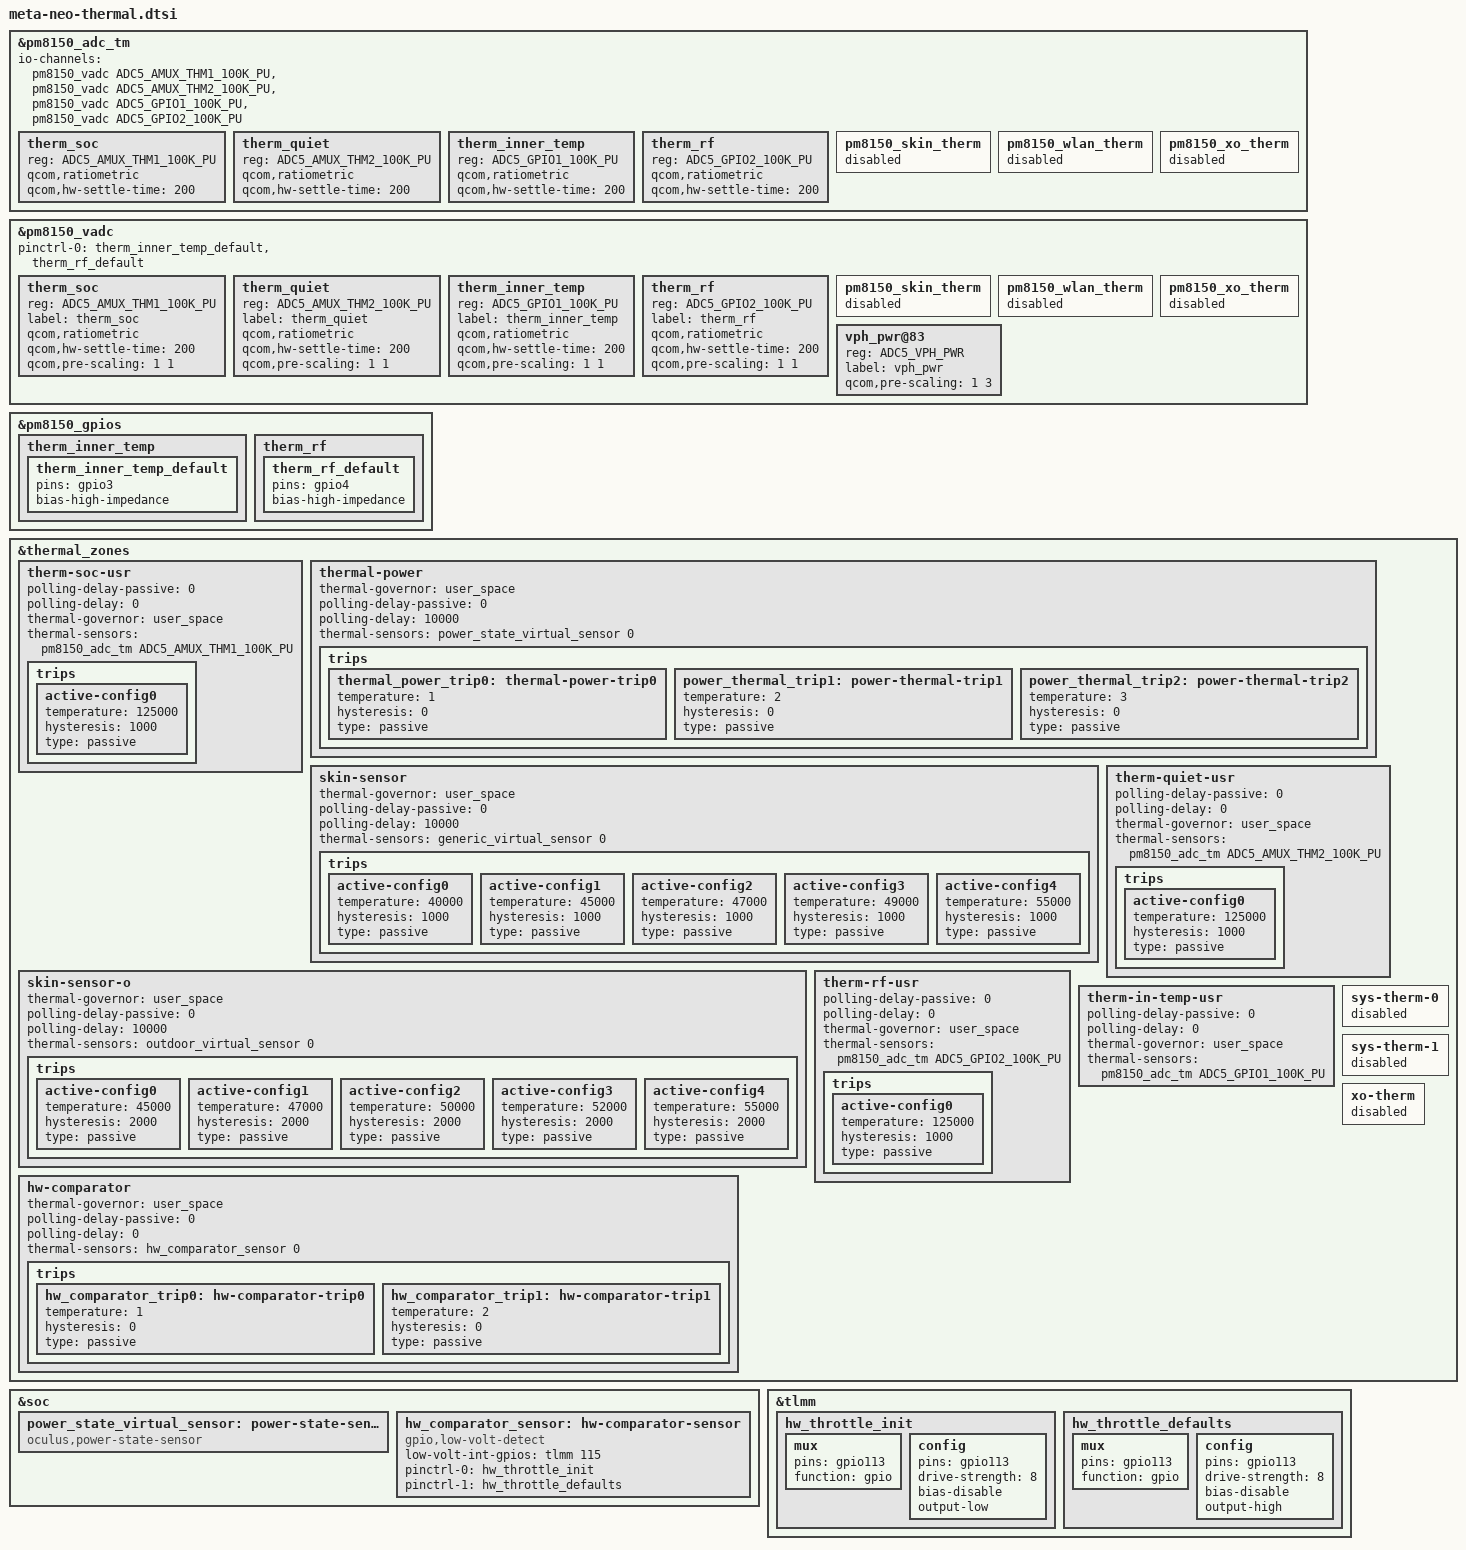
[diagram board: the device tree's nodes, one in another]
&pm8150_adc_tm {
	io-channels = <&pm8150_vadc ADC5_AMUX_THM1_100K_PU>,
				<&pm8150_vadc ADC5_AMUX_THM2_100K_PU>,
				<&pm8150_vadc ADC5_GPIO1_100K_PU>,
				<&pm8150_vadc ADC5_GPIO2_100K_PU>;

	therm_soc {
		reg = <ADC5_AMUX_THM1_100K_PU>;
		qcom,ratiometric;
		qcom,hw-settle-time = <200>;
	};

	therm_quiet {
		reg = <ADC5_AMUX_THM2_100K_PU>;
		qcom,ratiometric;
		qcom,hw-settle-time = <200>;
	};

	therm_inner_temp {
		reg = <ADC5_GPIO1_100K_PU>;
		qcom,ratiometric;
		qcom,hw-settle-time = <200>;
	};

	therm_rf {
		reg = <ADC5_GPIO2_100K_PU>;
		qcom,ratiometric;
		qcom,hw-settle-time = <200>;
	};

	pm8150_skin_therm {
		status = "disabled";
	};

	pm8150_wlan_therm {
		status = "disabled";
	};

	pm8150_xo_therm {
		status = "disabled";
	};
};

&pm8150_vadc {
	pinctrl-names = "default";
	pinctrl-0 = <&therm_inner_temp_default &therm_rf_default>;

	therm_soc {
		reg = <ADC5_AMUX_THM1_100K_PU>;
		label = "therm_soc";
		qcom,ratiometric;
		qcom,hw-settle-time = <200>;
		qcom,pre-scaling = <1 1>;
	};

	therm_quiet {
		reg = <ADC5_AMUX_THM2_100K_PU>;
		label = "therm_quiet";
		qcom,ratiometric;
		qcom,hw-settle-time = <200>;
		qcom,pre-scaling = <1 1>;
	};

	therm_inner_temp {
		reg = <ADC5_GPIO1_100K_PU>;
		label = "therm_inner_temp";
		qcom,ratiometric;
		qcom,hw-settle-time = <200>;
		qcom,pre-scaling = <1 1>;
	};

	therm_rf {
		reg = <ADC5_GPIO2_100K_PU>;
		label = "therm_rf";
		qcom,ratiometric;
		qcom,hw-settle-time = <200>;
		qcom,pre-scaling = <1 1>;
	};

	pm8150_skin_therm {
		status = "disabled";
	};

	pm8150_wlan_therm {
		status = "disabled";
	};

	pm8150_xo_therm {
		status = "disabled";
	};

	vph_pwr@83 {
		reg = <ADC5_VPH_PWR>;
		label = "vph_pwr";
		qcom,pre-scaling = <1 3>;
	};
};

&pm8150_gpios {
	therm_inner_temp {
		therm_inner_temp_default: therm_inner_temp_default {
			pins = "gpio3";
			bias-high-impedance;
		};
	};

	therm_rf {
		therm_rf_default: therm_rf_default {
			pins = "gpio4";
			bias-high-impedance;
		};
	};
};

&thermal_zones {
	therm-soc-usr {
		polling-delay-passive = <0>;
		polling-delay = <0>;
		thermal-governor = "user_space";
		thermal-sensors = <&pm8150_adc_tm ADC5_AMUX_THM1_100K_PU>;
		trips {
			active-config0 {
				temperature = <125000>;
				hysteresis = <1000>;
				type = "passive";
			};
		};
	};

	thermal-power {
		thermal-governor = "user_space";
		polling-delay-passive = <0>;
		polling-delay = <10000>;
		thermal-sensors = <&power_state_virtual_sensor 0>;
		trips {
			thermal_power_trip0: thermal-power-trip0 {
				temperature = <1>;
				hysteresis = <0>;
				type = "passive";
                        };
			power_thermal_trip1: power-thermal-trip1 {
				temperature = <2>;
				hysteresis = <0>;
				type = "passive";
			};
			power_thermal_trip2: power-thermal-trip2 {
				temperature = <3>;
				hysteresis = <0>;
				type = "passive";
			};
		};
	};

	skin-sensor {
		thermal-governor = "user_space";
		polling-delay-passive = <0>;
		polling-delay = <10000>;
		thermal-sensors = <&generic_virtual_sensor 0>;
		trips {
			active-config0 {
				temperature = <40000>;
				hysteresis = <1000>;
				type = "passive";
			};
			active-config1 {
				temperature = <45000>;
				hysteresis = <1000>;
				type = "passive";
			};
			active-config2 {
				temperature = <47000>;
				hysteresis = <1000>;
				type = "passive";
			};
			active-config3 {
				temperature = <49000>;
				hysteresis = <1000>;
				type = "passive";
			};
			active-config4 {
				temperature = <55000>;
				hysteresis = <1000>;
				type = "passive";
			};
		};
	};

	skin-sensor-o {
		thermal-governor = "user_space";
		polling-delay-passive = <0>;
		polling-delay = <10000>;
		thermal-sensors = <&outdoor_virtual_sensor 0>;
		trips {
			active-config0 {
				temperature = <45000>;
				hysteresis = <2000>;
				type = "passive";
			};
			active-config1 {
				temperature = <47000>;
				hysteresis = <2000>;
				type = "passive";
			};
			active-config2 {
				temperature = <50000>;
				hysteresis = <2000>;
				type = "passive";
			};
			active-config3 {
				temperature = <52000>;
				hysteresis = <2000>;
				type = "passive";
			};
			active-config4 {
				temperature = <55000>;
				hysteresis = <2000>;
				type = "passive";
			};
		};
	};

        therm-quiet-usr {
		polling-delay-passive = <0>;
		polling-delay = <0>;
		thermal-governor = "user_space";
		thermal-sensors = <&pm8150_adc_tm ADC5_AMUX_THM2_100K_PU>;
		trips {
			active-config0 {
				temperature = <125000>;
				hysteresis = <1000>;
				type = "passive";
			};
		};
	};

	therm-rf-usr {
		polling-delay-passive = <0>;
		polling-delay = <0>;
		thermal-governor = "user_space";
		thermal-sensors = <&pm8150_adc_tm ADC5_GPIO2_100K_PU>;
		trips {
			active-config0 {
				temperature = <125000>;
				hysteresis = <1000>;
				type = "passive";
			};
		};
	};

	therm-in-temp-usr {
		polling-delay-passive = <0>;
		polling-delay = <0>;
		thermal-governor = "user_space";
		thermal-sensors = <&pm8150_adc_tm ADC5_GPIO1_100K_PU>;
	};

	sys-therm-0 {
		status = "disabled";
	};

	sys-therm-1 {
		status = "disabled";
	};

	xo-therm {
		status = "disabled";
	};

	hw-comparator {
		thermal-governor = "user_space";
		polling-delay-passive = <0>;
		polling-delay = <0>;
		thermal-sensors = <&hw_comparator_sensor 0>;
		trips {
			hw_comparator_trip0: hw-comparator-trip0 {
				temperature = <1>;
				hysteresis = <0>;
				type = "passive";
                        };
			hw_comparator_trip1: hw-comparator-trip1 {
				temperature = <2>;
				hysteresis = <0>;
				type = "passive";
			};
		};
	};
};

&soc {
	power_state_virtual_sensor: power-state-sensor {
		compatible="oculus,power-state-sensor";
		#thermal-sensor-cells = <0>;
		status = "ok";
	};
};

&tlmm {
   hw_throttle_init: hw_throttle_init {
      mux {
          pins = "gpio113";
          function = "gpio";
      };

      config {
          pins = "gpio113";
          drive-strength = <8>;
          bias-disable;
          output-low;
      };
   };

   hw_throttle_defaults: hw_throttle_defaults {
      mux {
          pins = "gpio113";
          function = "gpio";
      };

      config {
          pins = "gpio113";
          drive-strength = <8>;
          bias-disable;
          output-high;
      };
   };
};

&soc {
	hw_comparator_sensor: hw-comparator-sensor {
		compatible = "gpio,low-volt-detect";
		#thermal-sensor-cells = <0>;
		low-volt-int-gpios = <&tlmm 115 GPIO_ACTIVE_HIGH>;
		pinctrl-names = "init", "default";
		pinctrl-0 = <&hw_throttle_init>;
		pinctrl-1 = <&hw_throttle_defaults>;
	};
};
